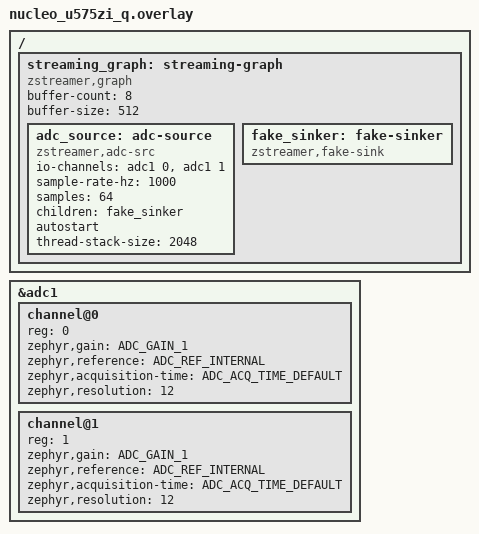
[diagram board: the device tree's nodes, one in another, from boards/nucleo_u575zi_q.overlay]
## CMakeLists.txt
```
# Copyright (c) 2026 zstreamer contributors
# SPDX-License-Identifier: Apache-2.0

cmake_minimum_required(VERSION 3.20.0)
find_package(Zephyr REQUIRED HINTS $ENV{ZEPHYR_BASE})
project(adc2fakesink)

target_sources(app PRIVATE src/main.c)
```

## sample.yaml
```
# Copyright (c) 2026 sharonthecreator
# SPDX-License-Identifier: Apache-2.0

sample:
  name: ADC-to-FakeSink
  description: |
    Captures ADC samples using timer-triggered DMA and discards them
    using a zstreamer graph with adc-src and fake-sink nodes.
    Demonstrates audio/signal capture at precise sample rates.
tests:
  sample.zstreamer.adc2fakesink:
    tags: zstreamer adc
    platform_allow: nucleo_u575zi_q
```

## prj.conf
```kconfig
# Copyright (c) 2026 sharonthecreator
# SPDX-License-Identifier: Apache-2.0

CONFIG_LOG=y

# zstreamer framework
CONFIG_ZSTREAMER=y

CONFIG_ZSTREAMER_ADC_SRC=y
CONFIG_ADC=y

# Test sink
CONFIG_ZSTREAMER_TEST_FAKE_SINK=y

# Heap memory for ADC DMA buffer allocation (if non-cacheable region not used)
CONFIG_HEAP_MEM_POOL_SIZE=4096
```

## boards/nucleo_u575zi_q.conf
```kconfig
# Copyright (c) 2026 zstreamer contributors
# SPDX-License-Identifier: Apache-2.0

# Enable STM32 ADC DMA support
CONFIG_ADC_STM32_DMA=y
CONFIG_DMA=y

# Counter/timer driver for ADC triggering
CONFIG_COUNTER=y
```

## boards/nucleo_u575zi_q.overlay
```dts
/*
 * Copyright (c) 2026 sharonthecreator
 * SPDX-License-Identifier: Apache-2.0
 *
 * ADC-to-FakeSink sample on Nucleo U575ZI-Q.
 *
 * Captures dual-channel 12-bit ADC data from PA0 (ADC1_IN0) and
 * PA1 (ADC1_IN1) at ~1 kHz using Zephyr's portable ADC API.
 */

&adc1 {
	status = "okay";
	#address-cells = <1>;
	#size-cells = <0>;

	channel@0 {
		reg = <0>;
		zephyr,gain = "ADC_GAIN_1";
		zephyr,reference = "ADC_REF_INTERNAL";
		zephyr,acquisition-time = <ADC_ACQ_TIME_DEFAULT>;
		zephyr,resolution = <12>;
	};

	channel@1 {
		reg = <1>;
		zephyr,gain = "ADC_GAIN_1";
		zephyr,reference = "ADC_REF_INTERNAL";
		zephyr,acquisition-time = <ADC_ACQ_TIME_DEFAULT>;
		zephyr,resolution = <12>;
	};
};

/ {
	streaming_graph: streaming-graph {
		compatible = "zstreamer,graph";
		buffer-count = <8>;
		buffer-size = <512>;

		adc_source: adc-source {
			compatible = "zstreamer,adc-src";
			io-channels = <&adc1 0>, <&adc1 1>;
			sample-rate-hz = <1000>;
			samples = <64>;
			children = <&fake_sinker>;
			autostart;
			thread-stack-size = <2048>;
		};

		fake_sinker: fake-sinker {
			compatible = "zstreamer,fake-sink";
		};
	};
};
```

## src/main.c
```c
/*
 * Copyright (c) 2026 sharonthecreator
 * SPDX-License-Identifier: Apache-2.0
 */

#include <zephyr/device.h>
#include <zephyr/kernel.h>
#include <zephyr/logging/log.h>

#include <zstreamer/source.h>

LOG_MODULE_REGISTER(adc2fakesink, LOG_LEVEL_INF);

#define ADC_SRC_NODE DT_NODELABEL(adc_source)

int main(void) {
  const struct device *adc_src = DEVICE_DT_GET(ADC_SRC_NODE);

  /* Pipeline starts automatically via DTS autostart property. */
  LOG_INF("ADC capture pipeline running (autostart)");

  /* Let it run for a while, then stop */
  k_sleep(K_SECONDS(10));

  LOG_INF("Stopping pipeline");
  zstreamer_source_stop(adc_src);

  LOG_INF("Done");
  return 0;
}
```
